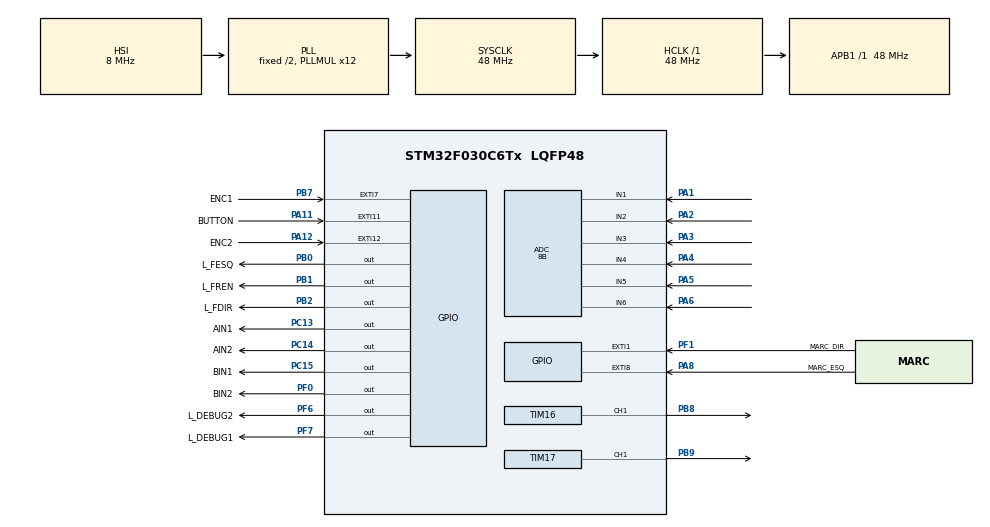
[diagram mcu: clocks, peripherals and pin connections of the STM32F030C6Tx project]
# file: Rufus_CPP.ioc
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ADC.ClockPrescaler=ADC_CLOCK_SYNC_PCLK_DIV4
ADC.ContinuousConvMode=ENABLE
ADC.DMAContinuousRequests=ENABLE
ADC.EOCSelection=ADC_EOC_SEQ_CONV
ADC.Overrun=ADC_OVR_DATA_OVERWRITTEN
ADC.Resolution=ADC_RESOLUTION_8B
ADC.SamplingTime=ADC_SAMPLETIME_41CYCLES_5
Dma.ADC.0.Direction=DMA_PERIPH_TO_MEMORY
Dma.ADC.0.Instance=DMA1_Channel1
Dma.ADC.0.MemDataAlignment=DMA_MDATAALIGN_BYTE
Dma.ADC.0.MemInc=DMA_MINC_ENABLE
Dma.ADC.0.Mode=DMA_CIRCULAR
Dma.ADC.0.PeriphDataAlignment=DMA_PDATAALIGN_BYTE
Dma.ADC.0.PeriphInc=DMA_PINC_DISABLE
Dma.ADC.0.Priority=DMA_PRIORITY_MEDIUM
Dma.Request0=ADC
Mcu.Family=STM32F0
Mcu.Name=STM32F030C6Tx
Mcu.Package=LQFP48
NVIC.ADC1_IRQn=true\:0\:0\:false\:false\:true\:true\:true
NVIC.DMA1_Channel1_IRQn=true\:0\:0\:false\:false\:true\:false\:true
NVIC.EXTI0_1_IRQn=true\:0\:0\:false\:false\:true\:true\:true
NVIC.EXTI4_15_IRQn=true\:0\:0\:false\:false\:true\:true\:true
NVIC.TIM1_BRK_UP_TRG_COM_IRQn=true\:0\:0\:false\:false\:true\:true\:true
NVIC.TIM1_CC_IRQn=true\:0\:0\:false\:false\:true\:true\:true
PA1.Mode=IN1
PA1.Signal=ADC_IN1
PA11.GPIO_Label=BUTTON
PA11.GPIO_ModeDefaultEXTI=GPIO_MODE_IT_RISING
PA11.Signal=GPXTI11
PA12.GPIO_Label=ENC2
PA12.Signal=GPXTI12
PA2.Mode=IN2
PA2.Signal=ADC_IN2
PA3.Mode=IN3
PA3.Signal=ADC_IN3
PA4.Mode=IN4
PA4.Signal=ADC_IN4
PA5.Mode=IN5
PA5.Signal=ADC_IN5
PA6.Mode=IN6
PA6.Signal=ADC_IN6
PA8.GPIO_Label=MARC_ESQ
PA8.GPIO_ModeDefaultEXTI=GPIO_MODE_IT_RISING_FALLING
PA8.Signal=GPXTI8
PB0.GPIO_Label=L_FESQ
PB0.Signal=GPIO_Output
PB1.GPIO_Label=L_FREN
PB1.Signal=GPIO_Output
PB2.GPIO_Label=L_FDIR
PB2.Signal=GPIO_Output
PB7.GPIO_Label=ENC1
PB7.Signal=GPXTI7
PB8.Signal=S_TIM16_CH1
PB9.Signal=S_TIM17_CH1
PC13.GPIO_Label=AIN1
PC13.Signal=GPIO_Output
PC14-OSC32_IN.GPIO_Label=AIN2
PC14-OSC32_IN.Signal=GPIO_Output
PC15-OSC32_OUT.GPIO_Label=BIN1
PC15-OSC32_OUT.Signal=GPIO_Output
PF0-OSC_IN.GPIO_Label=BIN2
PF0-OSC_IN.Signal=GPIO_Output
PF1-OSC_OUT.GPIO_Label=MARC_DIR
PF1-OSC_OUT.GPIO_ModeDefaultEXTI=GPIO_MODE_IT_RISING_FALLING
PF1-OSC_OUT.Signal=GPXTI1
PF6.GPIO_Label=L_DEBUG2
PF6.Signal=GPIO_Output
PF7.GPIO_Label=L_DEBUG1
PF7.Signal=GPIO_Output
ProjectManager.HeapSize=0x200
ProjectManager.StackSize=0x400
ProjectManager.TargetToolchain=STM32CubeIDE
RCC.AHBFreq_Value=48000000
RCC.APB1Freq_Value=48000000
RCC.APB1TimFreq_Value=48000000
RCC.HCLKFreq_Value=48000000
RCC.PLLMUL=RCC_PLL_MUL12
RCC.SYSCLKFreq_VALUE=48000000
RCC.SYSCLKSource=RCC_SYSCLKSOURCE_PLLCLK
SH.S_TIM16_CH1.0=TIM16_CH1,PWM Generation1 CH1
SH.S_TIM17_CH1.0=TIM17_CH1,PWM Generation1 CH1
TIM1.Period=14
TIM1.Prescaler=479
TIM1.TIM_MasterOutputTrigger=TIM_TRGO_UPDATE
TIM1.TIM_MasterSlaveMode=TIM_MASTERSLAVEMODE_DISABLE
TIM16.Channel=TIM_CHANNEL_1
TIM16.Period=255
TIM16.Prescaler=18
TIM17.Channel=TIM_CHANNEL_1
TIM17.Period=255
TIM17.Prescaler=18
VP_TIM16_VS_ClockSourceINT.Mode=Enable_Timer
VP_TIM17_VS_ClockSourceINT.Mode=Enable_Timer
VP_TIM1_VS_ClockSourceINT.Mode=Internal
board=custom

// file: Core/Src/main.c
/* USER CODE BEGIN Header */
/**
  ******************************************************************************
  * @file           : main.c
  * @brief          : Main program body
  ******************************************************************************
  * @attention
  *
  * <h2><center>&copy; Copyright (c) 2022 STMicroelectronics.
  * All rights reserved.</center></h2>
  *
  * This software component is licensed by ST under BSD 3-Clause license,
  * the "License"; You may not use this file except in compliance with the
  * License. You may obtain a copy of the License at:
  *                        opensource.org/licenses/BSD-3-Clause
  *
  ******************************************************************************
  */
/* USER CODE END Header */
#include "main.h"

ADC_HandleTypeDef hadc;
DMA_HandleTypeDef hdma_adc;

TIM_HandleTypeDef htim1;
TIM_HandleTypeDef htim16;
TIM_HandleTypeDef htim17;

void SystemClock_Config(void);
static void MX_GPIO_Init(void);
static void MX_DMA_Init(void);
static void MX_ADC_Init(void);
static void MX_TIM1_Init(void);
static void MX_TIM16_Init(void);
static void MX_TIM17_Init(void);

/* USER CODE BEGIN 0 */
uint8_t adcArray[BUFFER], check;
void HAL_ADC_ConvCpltCallback (ADC_HandleTypeDef * hadc) {
	ADC_Interrupt(adcArray, BUFFER);
}
void HAL_TIM_PeriodElapsedCallback(TIM_HandleTypeDef *htim)
{
  // Check which version of the timer triggered this callback and toggle LED
  if (htim == &htim1) {
	  TIM1_Interrupt();
  }
}
/* USER CODE END 0 */

int main(void)
{

  /* MCU Configuration--------------------------------------------------------*/

  /* Reset of all peripherals, Initializes the Flash interface and the Systick. */
  HAL_Init();

  /* Configure the system clock */
  SystemClock_Config();

  /* Initialize all configured peripherals */
  MX_GPIO_Init();
  MX_DMA_Init();
  MX_ADC_Init();
  MX_TIM1_Init();
  MX_TIM16_Init();
  MX_TIM17_Init();
  /* USER CODE BEGIN 2 */
  HAL_ADCEx_Calibration_Start(&hadc);
  HAL_ADC_Start_DMA(&hadc, (uint32_t *)adcArray, BUFFER);
  HAL_TIM_Base_Start_IT(&htim1);
  HAL_TIM_PWM_Start(&htim16, TIM_CHANNEL_1);
  HAL_TIM_PWM_Start(&htim17, TIM_CHANNEL_1);
  /* USER CODE END 2 */

  /* Infinite loop */
  while (1)
  {
	  CppMain();
  }
}

void SystemClock_Config(void)
{
  RCC_OscInitTypeDef RCC_OscInitStruct = {0};
  RCC_ClkInitTypeDef RCC_ClkInitStruct = {0};

  /** Initializes the RCC Oscillators according to the specified parameters
  * in the RCC_OscInitTypeDef structure.
  */
  RCC_OscInitStruct.OscillatorType = RCC_OSCILLATORTYPE_HSI;
  RCC_OscInitStruct.HSIState = RCC_HSI_ON;
  RCC_OscInitStruct.HSICalibrationValue = RCC_HSICALIBRATION_DEFAULT;
  RCC_OscInitStruct.PLL.PLLState = RCC_PLL_ON;
  RCC_OscInitStruct.PLL.PLLSource = RCC_PLLSOURCE_HSI;
  RCC_OscInitStruct.PLL.PLLMUL = RCC_PLL_MUL12;
  RCC_OscInitStruct.PLL.PREDIV = RCC_PREDIV_DIV1;
  if (HAL_RCC_OscConfig(&RCC_OscInitStruct) != HAL_OK)
  {
    Error_Handler();
  }
  /** Initializes the CPU, AHB and APB buses clocks
  */
  RCC_ClkInitStruct.ClockType = RCC_CLOCKTYPE_HCLK|RCC_CLOCKTYPE_SYSCLK
                              |RCC_CLOCKTYPE_PCLK1;
  RCC_ClkInitStruct.SYSCLKSource = RCC_SYSCLKSOURCE_PLLCLK;
  RCC_ClkInitStruct.AHBCLKDivider = RCC_SYSCLK_DIV1;
  RCC_ClkInitStruct.APB1CLKDivider = RCC_HCLK_DIV1;

  if (HAL_RCC_ClockConfig(&RCC_ClkInitStruct, FLASH_LATENCY_1) != HAL_OK)
  {
    Error_Handler();
  }
}

static void MX_ADC_Init(void)
{

  ADC_ChannelConfTypeDef sConfig = {0};

  /** Configure the global features of the ADC (Clock, Resolution, Data Alignment and number of conversion)
  */
  hadc.Instance = ADC1;
  hadc.Init.ClockPrescaler = ADC_CLOCK_SYNC_PCLK_DIV4;
  hadc.Init.Resolution = ADC_RESOLUTION_8B;
  hadc.Init.DataAlign = ADC_DATAALIGN_RIGHT;
  hadc.Init.ScanConvMode = ADC_SCAN_DIRECTION_FORWARD;
  hadc.Init.EOCSelection = ADC_EOC_SEQ_CONV;
  hadc.Init.LowPowerAutoWait = DISABLE;
  hadc.Init.LowPowerAutoPowerOff = DISABLE;
  hadc.Init.ContinuousConvMode = ENABLE;
  hadc.Init.DiscontinuousConvMode = DISABLE;
  hadc.Init.ExternalTrigConv = ADC_SOFTWARE_START;
  hadc.Init.ExternalTrigConvEdge = ADC_EXTERNALTRIGCONVEDGE_NONE;
  hadc.Init.DMAContinuousRequests = ENABLE;
  hadc.Init.Overrun = ADC_OVR_DATA_OVERWRITTEN;
  if (HAL_ADC_Init(&hadc) != HAL_OK)
  {
    Error_Handler();
  }
  /** Configure for the selected ADC regular channel to be converted.
  */
  sConfig.Channel = ADC_CHANNEL_1;
  sConfig.Rank = ADC_RANK_CHANNEL_NUMBER;
  sConfig.SamplingTime = ADC_SAMPLETIME_41CYCLES_5;
  if (HAL_ADC_ConfigChannel(&hadc, &sConfig) != HAL_OK)
  {
    Error_Handler();
  }
  /** Configure for the selected ADC regular channel to be converted.
  */
  sConfig.Channel = ADC_CHANNEL_2;
  if (HAL_ADC_ConfigChannel(&hadc, &sConfig) != HAL_OK)
  {
    Error_Handler();
  }
  /** Configure for the selected ADC regular channel to be converted.
  */
  sConfig.Channel = ADC_CHANNEL_3;
  if (HAL_ADC_ConfigChannel(&hadc, &sConfig) != HAL_OK)
  {
    Error_Handler();
  }
  /** Configure for the selected ADC regular channel to be converted.
  */
  sConfig.Channel = ADC_CHANNEL_4;
  if (HAL_ADC_ConfigChannel(&hadc, &sConfig) != HAL_OK)
  {
    Error_Handler();
  }
  /** Configure for the selected ADC regular channel to be converted.
  */
  sConfig.Channel = ADC_CHANNEL_5;
  if (HAL_ADC_ConfigChannel(&hadc, &sConfig) != HAL_OK)
  {
    Error_Handler();
  }
  /** Configure for the selected ADC regular channel to be converted.
  */
  sConfig.Channel = ADC_CHANNEL_6;
  if (HAL_ADC_ConfigChannel(&hadc, &sConfig) != HAL_OK)
  {
    Error_Handler();
  }

}

static void MX_TIM1_Init(void)
{

  TIM_ClockConfigTypeDef sClockSourceConfig = {0};
  TIM_MasterConfigTypeDef sMasterConfig = {0};

  htim1.Instance = TIM1;
  htim1.Init.Prescaler = 479;
  htim1.Init.CounterMode = TIM_COUNTERMODE_UP;
  htim1.Init.Period = 14;
  htim1.Init.ClockDivision = TIM_CLOCKDIVISION_DIV1;
  htim1.Init.RepetitionCounter = 0;
  htim1.Init.AutoReloadPreload = TIM_AUTORELOAD_PRELOAD_DISABLE;
  if (HAL_TIM_Base_Init(&htim1) != HAL_OK)
  {
    Error_Handler();
  }
  sClockSourceConfig.ClockSource = TIM_CLOCKSOURCE_INTERNAL;
  if (HAL_TIM_ConfigClockSource(&htim1, &sClockSourceConfig) != HAL_OK)
  {
    Error_Handler();
  }
  sMasterConfig.MasterOutputTrigger = TIM_TRGO_UPDATE;
  sMasterConfig.MasterSlaveMode = TIM_MASTERSLAVEMODE_DISABLE;
  if (HAL_TIMEx_MasterConfigSynchronization(&htim1, &sMasterConfig) != HAL_OK)
  {
    Error_Handler();
  }

}

static void MX_TIM16_Init(void)
{

  TIM_OC_InitTypeDef sConfigOC = {0};
  TIM_BreakDeadTimeConfigTypeDef sBreakDeadTimeConfig = {0};

  htim16.Instance = TIM16;
  htim16.Init.Prescaler = 18;
  htim16.Init.CounterMode = TIM_COUNTERMODE_UP;
  htim16.Init.Period = 255;
  htim16.Init.ClockDivision = TIM_CLOCKDIVISION_DIV1;
  htim16.Init.RepetitionCounter = 0;
  htim16.Init.AutoReloadPreload = TIM_AUTORELOAD_PRELOAD_DISABLE;
  if (HAL_TIM_Base_Init(&htim16) != HAL_OK)
  {
    Error_Handler();
  }
  if (HAL_TIM_PWM_Init(&htim16) != HAL_OK)
  {
    Error_Handler();
  }
  sConfigOC.OCMode = TIM_OCMODE_PWM1;
  sConfigOC.Pulse = 0;
  sConfigOC.OCPolarity = TIM_OCPOLARITY_HIGH;
  sConfigOC.OCNPolarity = TIM_OCNPOLARITY_HIGH;
  sConfigOC.OCFastMode = TIM_OCFAST_DISABLE;
  sConfigOC.OCIdleState = TIM_OCIDLESTATE_RESET;
  sConfigOC.OCNIdleState = TIM_OCNIDLESTATE_RESET;
  if (HAL_TIM_PWM_ConfigChannel(&htim16, &sConfigOC, TIM_CHANNEL_1) != HAL_OK)
  {
    Error_Handler();
  }
  sBreakDeadTimeConfig.OffStateRunMode = TIM_OSSR_DISABLE;
  sBreakDeadTimeConfig.OffStateIDLEMode = TIM_OSSI_DISABLE;
  sBreakDeadTimeConfig.LockLevel = TIM_LOCKLEVEL_OFF;
  sBreakDeadTimeConfig.DeadTime = 0;
  sBreakDeadTimeConfig.BreakState = TIM_BREAK_DISABLE;
  sBreakDeadTimeConfig.BreakPolarity = TIM_BREAKPOLARITY_HIGH;
  sBreakDeadTimeConfig.AutomaticOutput = TIM_AUTOMATICOUTPUT_DISABLE;
  if (HAL_TIMEx_ConfigBreakDeadTime(&htim16, &sBreakDeadTimeConfig) != HAL_OK)
  {
    Error_Handler();
  }
  HAL_TIM_MspPostInit(&htim16);

}

static void MX_TIM17_Init(void)
{

  TIM_OC_InitTypeDef sConfigOC = {0};
  TIM_BreakDeadTimeConfigTypeDef sBreakDeadTimeConfig = {0};

  htim17.Instance = TIM17;
  htim17.Init.Prescaler = 18;
  htim17.Init.CounterMode = TIM_COUNTERMODE_UP;
  htim17.Init.Period = 255;
  htim17.Init.ClockDivision = TIM_CLOCKDIVISION_DIV1;
  htim17.Init.RepetitionCounter = 0;
  htim17.Init.AutoReloadPreload = TIM_AUTORELOAD_PRELOAD_DISABLE;
  if (HAL_TIM_Base_Init(&htim17) != HAL_OK)
  {
    Error_Handler();
  }
  if (HAL_TIM_PWM_Init(&htim17) != HAL_OK)
  {
    Error_Handler();
  }
  sConfigOC.OCMode = TIM_OCMODE_PWM1;
  sConfigOC.Pulse = 0;
  sConfigOC.OCPolarity = TIM_OCPOLARITY_HIGH;
  sConfigOC.OCNPolarity = TIM_OCNPOLARITY_HIGH;
  sConfigOC.OCFastMode = TIM_OCFAST_DISABLE;
  sConfigOC.OCIdleState = TIM_OCIDLESTATE_RESET;
  sConfigOC.OCNIdleState = TIM_OCNIDLESTATE_RESET;
  if (HAL_TIM_PWM_ConfigChannel(&htim17, &sConfigOC, TIM_CHANNEL_1) != HAL_OK)
  {
    Error_Handler();
  }
  sBreakDeadTimeConfig.OffStateRunMode = TIM_OSSR_DISABLE;
  sBreakDeadTimeConfig.OffStateIDLEMode = TIM_OSSI_DISABLE;
  sBreakDeadTimeConfig.LockLevel = TIM_LOCKLEVEL_OFF;
  sBreakDeadTimeConfig.DeadTime = 0;
  sBreakDeadTimeConfig.BreakState = TIM_BREAK_DISABLE;
  sBreakDeadTimeConfig.BreakPolarity = TIM_BREAKPOLARITY_HIGH;
  sBreakDeadTimeConfig.AutomaticOutput = TIM_AUTOMATICOUTPUT_DISABLE;
  if (HAL_TIMEx_ConfigBreakDeadTime(&htim17, &sBreakDeadTimeConfig) != HAL_OK)
  {
    Error_Handler();
  }
  HAL_TIM_MspPostInit(&htim17);

}

static void MX_DMA_Init(void)
{

  /* DMA controller clock enable */
  __HAL_RCC_DMA1_CLK_ENABLE();

  /* DMA interrupt init */
  /* DMA1_Channel1_IRQn interrupt configuration */
  HAL_NVIC_SetPriority(DMA1_Channel1_IRQn, 0, 0);
  HAL_NVIC_EnableIRQ(DMA1_Channel1_IRQn);

}

static void MX_GPIO_Init(void)
{
  GPIO_InitTypeDef GPIO_InitStruct = {0};

  /* GPIO Ports Clock Enable */
  __HAL_RCC_GPIOC_CLK_ENABLE();
  __HAL_RCC_GPIOF_CLK_ENABLE();
  __HAL_RCC_GPIOA_CLK_ENABLE();
  __HAL_RCC_GPIOB_CLK_ENABLE();

  /*Configure GPIO pin Output Level */
  HAL_GPIO_WritePin(GPIOC, AIN1_Pin|AIN2_Pin|BIN1_Pin, GPIO_PIN_RESET);

  /*Configure GPIO pin Output Level */
  HAL_GPIO_WritePin(GPIOF, BIN2_Pin|L_DEBUG2_Pin|L_DEBUG1_Pin, GPIO_PIN_RESET);

  /*Configure GPIO pin Output Level */
  HAL_GPIO_WritePin(GPIOB, L_FESQ_Pin|L_FREN_Pin|L_FDIR_Pin, GPIO_PIN_RESET);

  /*Configure GPIO pins : AIN1_Pin AIN2_Pin BIN1_Pin */
  GPIO_InitStruct.Pin = AIN1_Pin|AIN2_Pin|BIN1_Pin;
  GPIO_InitStruct.Mode = GPIO_MODE_OUTPUT_PP;
  GPIO_InitStruct.Pull = GPIO_NOPULL;
  GPIO_InitStruct.Speed = GPIO_SPEED_FREQ_LOW;
  HAL_GPIO_Init(GPIOC, &GPIO_InitStruct);

  /*Configure GPIO pins : BIN2_Pin L_DEBUG2_Pin L_DEBUG1_Pin */
  GPIO_InitStruct.Pin = BIN2_Pin|L_DEBUG2_Pin|L_DEBUG1_Pin;
  GPIO_InitStruct.Mode = GPIO_MODE_OUTPUT_PP;
  GPIO_InitStruct.Pull = GPIO_NOPULL;
  GPIO_InitStruct.Speed = GPIO_SPEED_FREQ_LOW;
  HAL_GPIO_Init(GPIOF, &GPIO_InitStruct);

  /*Configure GPIO pin : MARC_DIR_Pin */
  GPIO_InitStruct.Pin = MARC_DIR_Pin;
  GPIO_InitStruct.Mode = GPIO_MODE_IT_RISING_FALLING;
  GPIO_InitStruct.Pull = GPIO_NOPULL;
  HAL_GPIO_Init(MARC_DIR_GPIO_Port, &GPIO_InitStruct);

  /*Configure GPIO pins : L_FESQ_Pin L_FREN_Pin L_FDIR_Pin */
  GPIO_InitStruct.Pin = L_FESQ_Pin|L_FREN_Pin|L_FDIR_Pin;
  GPIO_InitStruct.Mode = GPIO_MODE_OUTPUT_PP;
  GPIO_InitStruct.Pull = GPIO_NOPULL;
  GPIO_InitStruct.Speed = GPIO_SPEED_FREQ_LOW;
  HAL_GPIO_Init(GPIOB, &GPIO_InitStruct);

  /*Configure GPIO pin : MARC_ESQ_Pin */
  GPIO_InitStruct.Pin = MARC_ESQ_Pin;
  GPIO_InitStruct.Mode = GPIO_MODE_IT_RISING_FALLING;
  GPIO_InitStruct.Pull = GPIO_NOPULL;
  HAL_GPIO_Init(MARC_ESQ_GPIO_Port, &GPIO_InitStruct);

  /*Configure GPIO pins : BUTTON_Pin ENC2_Pin */
  GPIO_InitStruct.Pin = BUTTON_Pin|ENC2_Pin;
  GPIO_InitStruct.Mode = GPIO_MODE_IT_RISING;
  GPIO_InitStruct.Pull = GPIO_NOPULL;
  HAL_GPIO_Init(GPIOA, &GPIO_InitStruct);

  /*Configure GPIO pin : ENC1_Pin */
  GPIO_InitStruct.Pin = ENC1_Pin;
  GPIO_InitStruct.Mode = GPIO_MODE_IT_RISING;
  GPIO_InitStruct.Pull = GPIO_NOPULL;
  HAL_GPIO_Init(ENC1_GPIO_Port, &GPIO_InitStruct);

  /* EXTI interrupt init*/
  HAL_NVIC_SetPriority(EXTI0_1_IRQn, 0, 0);
  HAL_NVIC_EnableIRQ(EXTI0_1_IRQn);

  HAL_NVIC_SetPriority(EXTI4_15_IRQn, 0, 0);
  HAL_NVIC_EnableIRQ(EXTI4_15_IRQn);

}

void Error_Handler(void)
{
  __disable_irq();
  while (1)
  {
  }
}

/************************ (C) COPYRIGHT STMicroelectronics *****END OF FILE****/
